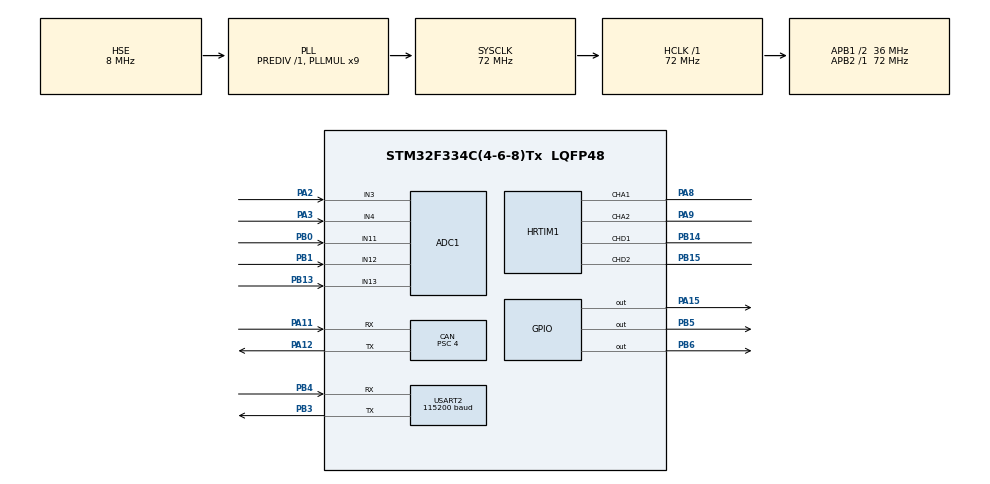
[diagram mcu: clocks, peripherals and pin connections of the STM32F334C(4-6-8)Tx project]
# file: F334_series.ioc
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ADC1.Channel-0\#ChannelRegularConversion=ADC_CHANNEL_3
ADC1.Channel-1\#ChannelRegularConversion=ADC_CHANNEL_4
ADC1.Channel-2\#ChannelRegularConversion=ADC_CHANNEL_11
ADC1.Channel-3\#ChannelRegularConversion=ADC_CHANNEL_12
ADC1.Channel-4\#ChannelRegularConversion=ADC_CHANNEL_13
ADC1.ClockPrescaler=ADC_CLOCK_SYNC_PCLK_DIV4
ADC1.ContinuousConvMode=ENABLE
ADC1.DMAContinuousRequests=ENABLE
ADC1.EOCSelection=ADC_EOC_SEQ_CONV
ADC1.NbrOfConversion=5
ADC1.NbrOfConversionFlag=1
ADC1.Offset-0\#ChannelRegularConversion=0
ADC1.Offset-1\#ChannelRegularConversion=0
ADC1.Offset-2\#ChannelRegularConversion=0
ADC1.Offset-3\#ChannelRegularConversion=0
ADC1.Offset-4\#ChannelRegularConversion=0
ADC1.OffsetNumber-0\#ChannelRegularConversion=ADC_OFFSET_NONE
ADC1.OffsetNumber-1\#ChannelRegularConversion=ADC_OFFSET_NONE
ADC1.OffsetNumber-2\#ChannelRegularConversion=ADC_OFFSET_NONE
ADC1.OffsetNumber-3\#ChannelRegularConversion=ADC_OFFSET_NONE
ADC1.OffsetNumber-4\#ChannelRegularConversion=ADC_OFFSET_NONE
ADC1.Rank-0\#ChannelRegularConversion=1
ADC1.Rank-1\#ChannelRegularConversion=2
ADC1.Rank-2\#ChannelRegularConversion=3
ADC1.Rank-3\#ChannelRegularConversion=4
ADC1.Rank-4\#ChannelRegularConversion=5
ADC1.SamplingTime-0\#ChannelRegularConversion=ADC_SAMPLETIME_601CYCLES_5
ADC1.SamplingTime-1\#ChannelRegularConversion=ADC_SAMPLETIME_601CYCLES_5
ADC1.SamplingTime-2\#ChannelRegularConversion=ADC_SAMPLETIME_601CYCLES_5
ADC1.SamplingTime-3\#ChannelRegularConversion=ADC_SAMPLETIME_601CYCLES_5
ADC1.SamplingTime-4\#ChannelRegularConversion=ADC_SAMPLETIME_601CYCLES_5
ADC1.SamplingTimeOPAMP-1\#ChannelRegularConversion=ADC_SAMPLETIME_7CYCLES_5
ADC1.SamplingTimeOPAMP-2\#ChannelRegularConversion=ADC_SAMPLETIME_7CYCLES_5
ADC1.SamplingTimeOPAMP-3\#ChannelRegularConversion=ADC_SAMPLETIME_7CYCLES_5
ADC1.SamplingTimeOPAMP-4\#ChannelRegularConversion=ADC_SAMPLETIME_7CYCLES_5
ADC1.SubFamily=STM32F334x8
ADC1.master=1
CAN.ABOM=DISABLE
CAN.BS1=CAN_BS1_6TQ
CAN.BS2=CAN_BS2_2TQ
CAN.CalculateBaudRate=1000000
CAN.CalculateTimeBit=1000
CAN.CalculateTimeQuantum=111.11111111111111
CAN.NART=DISABLE
CAN.Prescaler=4
CAN.SJW=CAN_SJW_2TQ
CAN.TXFP=DISABLE
Dma.ADC1.0.Direction=DMA_PERIPH_TO_MEMORY
Dma.ADC1.0.Instance=DMA1_Channel1
Dma.ADC1.0.MemDataAlignment=DMA_MDATAALIGN_WORD
Dma.ADC1.0.MemInc=DMA_MINC_ENABLE
Dma.ADC1.0.Mode=DMA_CIRCULAR
Dma.ADC1.0.PeriphDataAlignment=DMA_PDATAALIGN_WORD
Dma.ADC1.0.PeriphInc=DMA_PINC_DISABLE
Dma.ADC1.0.Priority=DMA_PRIORITY_LOW
Dma.Request0=ADC1
Dma.Request1=USART2_TX
Dma.USART2_TX.1.Direction=DMA_MEMORY_TO_PERIPH
Dma.USART2_TX.1.Instance=DMA1_Channel7
Dma.USART2_TX.1.MemDataAlignment=DMA_MDATAALIGN_BYTE
Dma.USART2_TX.1.MemInc=DMA_MINC_ENABLE
Dma.USART2_TX.1.Mode=DMA_NORMAL
Dma.USART2_TX.1.PeriphDataAlignment=DMA_PDATAALIGN_BYTE
Dma.USART2_TX.1.PeriphInc=DMA_PINC_DISABLE
Dma.USART2_TX.1.Priority=DMA_PRIORITY_LOW
HRTIM1.CompareUnit1-MasterTimer=HRTIM_COMPAREUNIT_1
HRTIM1.CompareUnit1-Output_TA1TA2=HRTIM_COMPAREUNIT_1
HRTIM1.CompareUnit1-Output_TD1TD2=HRTIM_COMPAREUNIT_1
HRTIM1.CompareUnit2-Output_TA1TA2=HRTIM_COMPAREUNIT_2
HRTIM1.CompareUnit2-Output_TD1TD2=HRTIM_COMPAREUNIT_2
HRTIM1.CompareValue1-MasterTimer=46080
HRTIM1.CompareValue1-Output_TA1TA2=46080
HRTIM1.CompareValue1-Output_TD1TD2=46080
HRTIM1.CompareValue2-Output_TA1TA2=46080
HRTIM1.CompareValue2-Output_TD1TD2=46080
HRTIM1.DeadTimeInsertion-Output_TA1TA2=HRTIM_TIMDEADTIMEINSERTION_ENABLED
HRTIM1.DeadTimeInsertion-Output_TD1TD2=HRTIM_TIMDEADTIMEINSERTION_ENABLED
HRTIM1.FallingValue-Output_TA1TA2=300
HRTIM1.FallingValue-Output_TD1TD2=200
HRTIM1.NumberResetSource1-Output_TA1TA2=1
HRTIM1.NumberResetSource1-Output_TD1TD2=1
HRTIM1.NumberResetTrigger-Output_TA1TA2=1
HRTIM1.NumberResetTrigger-Output_TD1TD2=1
HRTIM1.NumberSetSource1-Output_TA1TA2=1
HRTIM1.NumberSetSource1-Output_TD1TD2=1
HRTIM1.Periode_MASTER=46080
HRTIM1.Periode_TA=46080
HRTIM1.Periode_TD=46080
HRTIM1.PreloadEnable-MasterTimer=HRTIM_PRELOAD_ENABLED
HRTIM1.PreloadEnable-Output_TA1TA2=HRTIM_PRELOAD_ENABLED
HRTIM1.PreloadEnable-Output_TD1TD2=HRTIM_PRELOAD_ENABLED
HRTIM1.PrescalerDead-Output_TD1TD2=HRTIM_TIMDEADTIME_PRESCALERRATIO_MUL4
HRTIM1.PrescalerRatio_MASTER=HRTIM_PRESCALERRATIO_MUL32
HRTIM1.PrescalerRatio_TA=HRTIM_PRESCALERRATIO_MUL32
HRTIM1.PrescalerRatio_TD=HRTIM_PRESCALERRATIO_MUL32
HRTIM1.RepetitionUpdate-MasterTimer=HRTIM_UPDATEONREPETITION_ENABLED
HRTIM1.RepetitionUpdate-Output_TA1TA2=HRTIM_UPDATEONREPETITION_ENABLED
HRTIM1.RepetitionUpdate-Output_TD1TD2=HRTIM_UPDATEONREPETITION_ENABLED
HRTIM1.ResetOutput1_Source1-Output_TA1TA2=HRTIM_OUTPUTRESET_TIMCMP1
HRTIM1.ResetOutput1_Source1-Output_TD1TD2=HRTIM_OUTPUTRESET_MASTERCMP1
HRTIM1.ResetTrigger1-Output_TA1TA2=HRTIM_TIMRESETTRIGGER_MASTER_PER
HRTIM1.ResetTrigger1-Output_TD1TD2=HRTIM_TIMRESETTRIGGER_MASTER_PER
HRTIM1.RisingValue-Output_TA1TA2=300
HRTIM1.RisingValue-Output_TD1TD2=200
HRTIM1.SetOutput1_Source1-Output_TA1TA2=HRTIM_OUTPUTSET_MASTERCMP1
HRTIM1.SetOutput1_Source1-Output_TD1TD2=HRTIM_OUTPUTSET_TIMCMP1
Mcu.Family=STM32F3
Mcu.Name=STM32F334C(4-6-8)Tx
Mcu.Package=LQFP48
NVIC.ADC1_2_IRQn=true\:0\:0\:false\:false\:true\:true\:true
NVIC.CAN_RX0_IRQn=true\:0\:0\:false\:false\:true\:true\:true
NVIC.DMA1_Channel1_IRQn=true\:0\:0\:false\:false\:true\:false\:true
NVIC.DMA1_Channel7_IRQn=true\:0\:0\:false\:false\:true\:false\:true
NVIC.PriorityGroup=NVIC_PRIORITYGROUP_4
NVIC.TIM2_IRQn=true\:0\:0\:false\:false\:true\:true\:true
PA11.Mode=CAN_Activate
PA11.Signal=CAN_RX
PA12.Mode=CAN_Activate
PA12.Signal=CAN_TX
PA13.Mode=Serial_Wire
PA13.Signal=SYS_JTMS-SWDIO
PA14.Mode=Serial_Wire
PA14.Signal=SYS_JTCK-SWCLK
PA15.Signal=GPIO_Output
PA2.Mode=IN3-Single-Ended
PA2.Signal=ADC1_IN3
PA3.Mode=IN4-Single-Ended
PA3.Signal=ADC1_IN4
PA8.Mode=Output_TA1TA2
PA8.Signal=HRTIM1_CHA1
PA9.Mode=Output_TA1TA2
PA9.Signal=HRTIM1_CHA2
PB0.Mode=IN11-Single-Ended
PB0.Signal=ADC1_IN11
PB1.Mode=IN12-Single-Ended
PB1.Signal=ADC1_IN12
PB13.Mode=IN13-Single-Ended
PB13.Signal=ADC1_IN13
PB14.Mode=Output_TD1TD2
PB14.Signal=HRTIM1_CHD1
PB15.Mode=Output_TD1TD2
PB15.Signal=HRTIM1_CHD2
PB3.Mode=Asynchronous
PB3.Signal=USART2_TX
PB4.Mode=Asynchronous
PB4.Signal=USART2_RX
PB5.Signal=GPIO_Output
PB6.Signal=GPIO_Output
PF0\ /\ OSC_IN.Mode=HSE-External-Oscillator
PF0\ /\ OSC_IN.Signal=RCC_OSC_IN
PF1\ /\ OSC_OUT.Mode=HSE-External-Oscillator
PF1\ /\ OSC_OUT.Signal=RCC_OSC_OUT
ProjectManager.HeapSize=0x200
ProjectManager.StackSize=0x400
ProjectManager.TargetToolchain=MDK-ARM V5.32
RCC.AHBFreq_Value=72000000
RCC.APB1CLKDivider=RCC_HCLK_DIV2
RCC.APB1Freq_Value=36000000
RCC.APB1TimFreq_Value=72000000
RCC.APB2Freq_Value=72000000
RCC.APB2TimFreq_Value=72000000
RCC.CortexFreq_Value=72000000
RCC.HCLKFreq_Value=72000000
RCC.HRTIMSelection=RCC_HRTIM1CLK_PLLCLK
RCC.HSE_VALUE=8000000
RCC.HSI_VALUE=8000000
RCC.LSE_VALUE=32768
RCC.PLLMUL=RCC_PLL_MUL9
RCC.PLLSourceVirtual=RCC_PLLSOURCE_HSE
RCC.SYSCLKFreq_VALUE=72000000
RCC.SYSCLKSourceVirtual=RCC_SYSCLKSOURCE_PLLCLK
TIM2.AutoReloadPreload=TIM_AUTORELOAD_PRELOAD_ENABLE
TIM2.Period=99
TIM2.Prescaler=71
USART2.BaudRate=115200
USART2.VirtualMode-Asynchronous=VM_ASYNC
VP_HRTIM1_VS_hrtimMasterTimerNoOutput.Mode=MasterTimer
VP_TIM2_VS_ClockSourceINT.Mode=Internal
board=custom

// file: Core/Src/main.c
/* USER CODE BEGIN Header */
/**
  ******************************************************************************
  * @file           : main.c
  * @brief          : Main program body
  ******************************************************************************
  * @attention
  *
  * Copyright (c) 2023 STMicroelectronics.
  * All rights reserved.
  *
  * This software is licensed under terms that can be found in the LICENSE file
  * in the root directory of this software component.
  * If no LICENSE file comes with this software, it is provided AS-IS.
  *
  ******************************************************************************
  */
/* USER CODE END Header */
#include "main.h"
#include "adc.h"
#include "can.h"
#include "dma.h"
#include "hrtim.h"
#include "usart.h"
#include "gpio.h"

/* USER CODE BEGIN Includes */
#include "function.h"
/* USER CODE END Includes */

void SystemClock_Config(void);

int main(void)
{

  /* MCU Configuration--------------------------------------------------------*/

  /* Reset of all peripherals, Initializes the Flash interface and the Systick. */
  HAL_Init();

  /* Configure the system clock */
  SystemClock_Config();

  /* Initialize all configured peripherals */
  MX_GPIO_Init();
  MX_DMA_Init();
  MX_ADC1_Init();
  MX_HRTIM1_Init();
  MX_TIM2_Init();
  MX_USART2_UART_Init();
  MX_CAN_Init();
  /* USER CODE BEGIN 2 */
	WorkInit();
  /* USER CODE END 2 */

  /* Infinite loop */
  while (1)
  {

  }
}

void SystemClock_Config(void)
{
  RCC_OscInitTypeDef RCC_OscInitStruct = {0};
  RCC_ClkInitTypeDef RCC_ClkInitStruct = {0};
  RCC_PeriphCLKInitTypeDef PeriphClkInit = {0};

  /** Initializes the RCC Oscillators according to the specified parameters
  * in the RCC_OscInitTypeDef structure.
  */
  RCC_OscInitStruct.OscillatorType = RCC_OSCILLATORTYPE_HSE;
  RCC_OscInitStruct.HSEState = RCC_HSE_ON;
  RCC_OscInitStruct.HSEPredivValue = RCC_HSE_PREDIV_DIV1;
  RCC_OscInitStruct.HSIState = RCC_HSI_ON;
  RCC_OscInitStruct.PLL.PLLState = RCC_PLL_ON;
  RCC_OscInitStruct.PLL.PLLSource = RCC_PLLSOURCE_HSE;
  RCC_OscInitStruct.PLL.PLLMUL = RCC_PLL_MUL9;
  if (HAL_RCC_OscConfig(&RCC_OscInitStruct) != HAL_OK)
  {
    Error_Handler();
  }
  /** Initializes the CPU, AHB and APB buses clocks
  */
  RCC_ClkInitStruct.ClockType = RCC_CLOCKTYPE_HCLK|RCC_CLOCKTYPE_SYSCLK
                              |RCC_CLOCKTYPE_PCLK1|RCC_CLOCKTYPE_PCLK2;
  RCC_ClkInitStruct.SYSCLKSource = RCC_SYSCLKSOURCE_PLLCLK;
  RCC_ClkInitStruct.AHBCLKDivider = RCC_SYSCLK_DIV1;
  RCC_ClkInitStruct.APB1CLKDivider = RCC_HCLK_DIV2;
  RCC_ClkInitStruct.APB2CLKDivider = RCC_HCLK_DIV1;

  if (HAL_RCC_ClockConfig(&RCC_ClkInitStruct, FLASH_LATENCY_2) != HAL_OK)
  {
    Error_Handler();
  }
  PeriphClkInit.PeriphClockSelection = RCC_PERIPHCLK_HRTIM1;
  PeriphClkInit.Hrtim1ClockSelection = RCC_HRTIM1CLK_PLLCLK;
  if (HAL_RCCEx_PeriphCLKConfig(&PeriphClkInit) != HAL_OK)
  {
    Error_Handler();
  }
}

void Error_Handler(void)
{
  __disable_irq();
  while (1)
  {
  }
}
